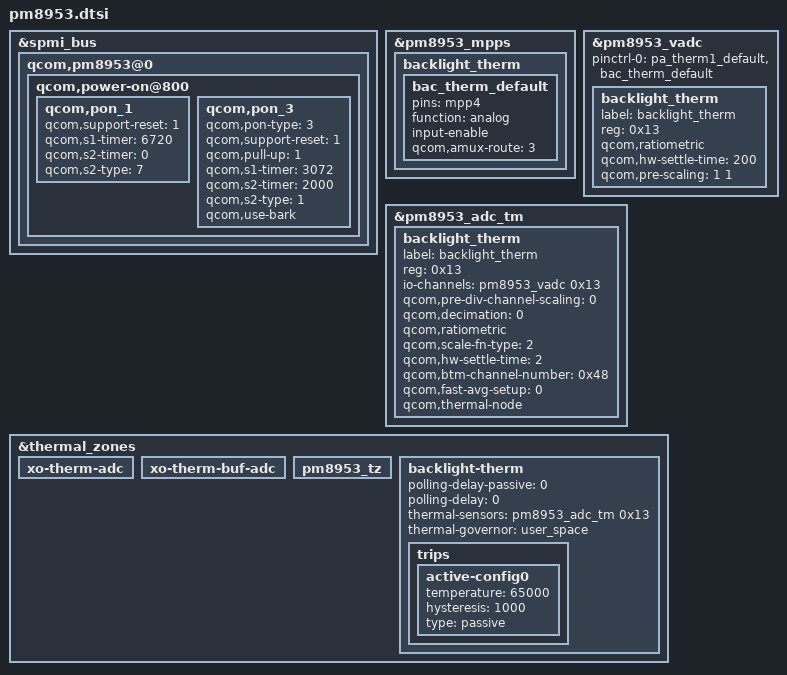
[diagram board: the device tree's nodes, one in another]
/* From stock pm8953.dtsi */
&spmi_bus {
	qcom,pm8953@0 {
		qcom,power-on@800 {
			qcom,pon_1 {
				qcom,support-reset = <1>;
				qcom,s1-timer = <6720>;
				qcom,s2-timer = <0>;
				qcom,s2-type = <7>;
			};

			qcom,pon_3 {
				qcom,pon-type = <3>;
				qcom,support-reset = <1>;
				qcom,pull-up = <1>;
				qcom,s1-timer = <3072>;
				qcom,s2-timer = <2000>;
				qcom,s2-type = <1>;
				qcom,use-bark;
			};
		};
	};
};

&pm8953_mpps {
	/* WARNING: Redefine node */
	/delete-node/ case_therm;
	backlight_therm {
		bac_therm_default: bac_therm_default {
			pins = "mpp4";
			function = "analog";
			input-enable;
			qcom,amux-route = <3>;
		};
	};
};

&pm8953_vadc {
	pinctrl-0 = <&pa_therm1_default &bac_therm_default>;
	/delete-node/ case_therm;
	backlight_therm {
		label = "backlight_therm";
		reg = <0x13>;
		qcom,ratiometric;
		qcom,hw-settle-time = <200>;
		qcom,pre-scaling = <1 1>;
	};
};

&pm8953_adc_tm {
	/delete-node/ pa_therm0;
	backlight_therm {
		label = "backlight_therm";
		reg = <0x13>;
		io-channels = <&pm8953_vadc 0x13>;
		io-channel-names = "backlight_therm";
		qcom,pre-div-channel-scaling = <0>;
		qcom,decimation = <0>;
		qcom,ratiometric;
		qcom,scale-fn-type = <2>;
		qcom,hw-settle-time = <2>;
		qcom,btm-channel-number = <0x48>;
		qcom,fast-avg-setup = <0>;
		qcom,thermal-node;
	};
};

&thermal_zones {
	xo-therm-adc {
		/delete-property/ wake-capable-sensor;
	};

	xo-therm-buf-adc {
		/delete-property/ wake-capable-sensor;
	};

	pm8953_tz {
		/delete-property/ wake-capable-sensor;
	};

	backlight-therm {
		polling-delay-passive = <0>;
		polling-delay = <0>;
		thermal-sensors = <&pm8953_adc_tm 0x13>;
		thermal-governor = "user_space";

		trips {
			active-config0 {
				temperature = <65000>;
				hysteresis = <1000>;
				type = "passive";
			};
		};
	};
};
